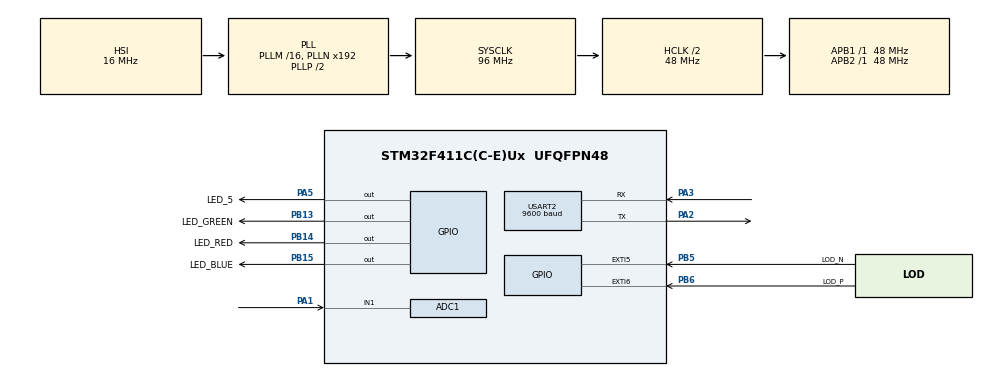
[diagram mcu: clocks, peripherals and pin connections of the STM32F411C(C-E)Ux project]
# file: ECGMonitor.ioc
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ADC1.Channel-3\#ChannelRegularConversion=ADC_CHANNEL_1
ADC1.ClockPrescaler=ADC_CLOCK_SYNC_PCLK_DIV6
ADC1.ContinuousConvMode=DISABLE
ADC1.DMAContinuousRequests=ENABLE
ADC1.ExternalTrigConv=ADC_EXTERNALTRIGCONV_T2_TRGO
ADC1.NbrOfConversion=1
ADC1.NbrOfConversionFlag=1
ADC1.Rank-3\#ChannelRegularConversion=1
ADC1.SamplingTime-3\#ChannelRegularConversion=ADC_SAMPLETIME_3CYCLES
ADC1.master=1
Dma.ADC1.0.Direction=DMA_PERIPH_TO_MEMORY
Dma.ADC1.0.FIFOMode=DMA_FIFOMODE_DISABLE
Dma.ADC1.0.Instance=DMA2_Stream0
Dma.ADC1.0.MemDataAlignment=DMA_MDATAALIGN_HALFWORD
Dma.ADC1.0.MemInc=DMA_MINC_ENABLE
Dma.ADC1.0.Mode=DMA_CIRCULAR
Dma.ADC1.0.PeriphDataAlignment=DMA_PDATAALIGN_HALFWORD
Dma.ADC1.0.PeriphInc=DMA_PINC_DISABLE
Dma.ADC1.0.Priority=DMA_PRIORITY_HIGH
Dma.Request0=ADC1
Mcu.Family=STM32F4
Mcu.Name=STM32F411C(C-E)Ux
Mcu.Package=UFQFPN48
NVIC.DMA2_Stream0_IRQn=true\:0\:0\:false\:false\:true\:false\:true\:true
NVIC.EXTI9_5_IRQn=true\:0\:0\:false\:false\:true\:true\:true\:true
NVIC.PriorityGroup=NVIC_PRIORITYGROUP_4
NVIC.TIM2_IRQn=true\:0\:0\:false\:false\:true\:true\:true\:true
PA1.Signal=ADCx_IN1
PA2.Mode=Asynchronous
PA2.Signal=USART2_TX
PA3.Mode=Asynchronous
PA3.Signal=USART2_RX
PA5.GPIO_Label=LED_5
PA5.GPIO_Speed=GPIO_SPEED_FREQ_MEDIUM
PA5.Signal=GPIO_Output
PB13.GPIO_Label=LED_GREEN
PB13.PinState=GPIO_PIN_SET
PB13.Signal=GPIO_Output
PB14.GPIO_Label=LED_RED
PB14.Signal=GPIO_Output
PB15.GPIO_Label=LED_BLUE
PB15.PinState=GPIO_PIN_SET
PB15.Signal=GPIO_Output
PB5.GPIO_Label=LOD_N
PB5.GPIO_ModeDefaultEXTI=GPIO_MODE_IT_RISING_FALLING
PB5.Signal=GPXTI5
PB6.GPIO_Label=LOD_P
PB6.GPIO_ModeDefaultEXTI=GPIO_MODE_IT_RISING_FALLING
PB6.Signal=GPXTI6
PH0\ -\ OSC_IN.Mode=HSE-External-Oscillator
PH0\ -\ OSC_IN.Signal=RCC_OSC_IN
PH1\ -\ OSC_OUT.Mode=HSE-External-Oscillator
PH1\ -\ OSC_OUT.Signal=RCC_OSC_OUT
ProjectManager.HeapSize=0x200
ProjectManager.StackSize=0x400
ProjectManager.TargetToolchain=Makefile
RCC.AHBCLKDivider=RCC_SYSCLK_DIV2
RCC.AHBFreq_Value=48000000
RCC.APB1Freq_Value=48000000
RCC.APB1TimFreq_Value=48000000
RCC.APB2Freq_Value=48000000
RCC.APB2TimFreq_Value=48000000
RCC.CortexFreq_Value=48000000
RCC.HCLKFreq_Value=48000000
RCC.HSE_VALUE=8000000
RCC.HSI_VALUE=16000000
RCC.LSE_VALUE=32768
RCC.SYSCLKFreq_VALUE=96000000
RCC.SYSCLKSource=RCC_SYSCLKSOURCE_PLLCLK
RCC.VCOOutputFreq_Value=192000000
SH.ADCx_IN1.0=ADC1_IN1,IN1
TIM2.AutoReloadPreload=TIM_AUTORELOAD_PRELOAD_ENABLE
TIM2.Channel-PWM\ Generation1\ No\ Output=TIM_CHANNEL_1
TIM2.ClockDivision=TIM_CLOCKDIVISION_DIV1
TIM2.Period=512
TIM2.TIM_MasterOutputTrigger=TIM_TRGO_UPDATE
USART2.BaudRate=9600
USART2.Parity=PARITY_NONE
USART2.VirtualMode=VM_ASYNC
USART2.WordLength=WORDLENGTH_8B
VP_TIM2_VS_ClockSourceINT.Mode=Internal
VP_TIM2_VS_no_output1.Mode=PWM Generation1 No Output
board=custom

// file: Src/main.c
/* USER CODE BEGIN Header */
/**
  ******************************************************************************
  * @file           : main.c
  * @brief          : Main program body
  ******************************************************************************
  * @attention
  *
  * Copyright (c) 2023 STMicroelectronics.
  * All rights reserved.
  *
  * This software is licensed under terms that can be found in the LICENSE file
  * in the root directory of this software component.
  * If no LICENSE file comes with this software, it is provided AS-IS.
  *
  ******************************************************************************
  */
/* USER CODE END Header */
#include "main.h"
#include "adc.h"
#include "dma.h"
#include "tim.h"
#include "usart.h"
#include "gpio.h"

/* USER CODE BEGIN Includes */
#include "serial/print.h"
#include "adc_buffer.h"
/* USER CODE END Includes */

void SystemClock_Config(void);

int main(void)
{

  /* MCU Configuration--------------------------------------------------------*/

  /* Reset of all peripherals, Initializes the Flash interface and the Systick. */
  HAL_Init();

  /* Configure the system clock */
  SystemClock_Config();

  /* Initialize all configured peripherals */
  MX_GPIO_Init();
  MX_DMA_Init();
  MX_ADC1_Init();
  MX_USART2_UART_Init();
  MX_TIM2_Init();
  /* USER CODE BEGIN 2 */

  HAL_TIM_Base_Start_IT(&htim2);

  HAL_ADC_Start_DMA(&hadc1, (uint32_t*)adc_buffer, ADC_BUF_LEN);

  cpp_main();
  /* USER CODE END 2 */

  /* Infinite loop */
  while (1)
  {

  }
}

void SystemClock_Config(void)
{
  RCC_OscInitTypeDef RCC_OscInitStruct = {0};
  RCC_ClkInitTypeDef RCC_ClkInitStruct = {0};

  /** Configure the main internal regulator output voltage
  */
  __HAL_RCC_PWR_CLK_ENABLE();
  __HAL_PWR_VOLTAGESCALING_CONFIG(PWR_REGULATOR_VOLTAGE_SCALE1);

  /** Initializes the RCC Oscillators according to the specified parameters
  * in the RCC_OscInitTypeDef structure.
  */
  RCC_OscInitStruct.OscillatorType = RCC_OSCILLATORTYPE_HSI;
  RCC_OscInitStruct.HSIState = RCC_HSI_ON;
  RCC_OscInitStruct.HSICalibrationValue = RCC_HSICALIBRATION_DEFAULT;
  RCC_OscInitStruct.PLL.PLLState = RCC_PLL_ON;
  RCC_OscInitStruct.PLL.PLLSource = RCC_PLLSOURCE_HSI;
  RCC_OscInitStruct.PLL.PLLM = 16;
  RCC_OscInitStruct.PLL.PLLN = 192;
  RCC_OscInitStruct.PLL.PLLP = RCC_PLLP_DIV2;
  RCC_OscInitStruct.PLL.PLLQ = 4;
  if (HAL_RCC_OscConfig(&RCC_OscInitStruct) != HAL_OK)
  {
    Error_Handler();
  }

  /** Initializes the CPU, AHB and APB buses clocks
  */
  RCC_ClkInitStruct.ClockType = RCC_CLOCKTYPE_HCLK|RCC_CLOCKTYPE_SYSCLK
                              |RCC_CLOCKTYPE_PCLK1|RCC_CLOCKTYPE_PCLK2;
  RCC_ClkInitStruct.SYSCLKSource = RCC_SYSCLKSOURCE_PLLCLK;
  RCC_ClkInitStruct.AHBCLKDivider = RCC_SYSCLK_DIV2;
  RCC_ClkInitStruct.APB1CLKDivider = RCC_HCLK_DIV1;
  RCC_ClkInitStruct.APB2CLKDivider = RCC_HCLK_DIV1;

  if (HAL_RCC_ClockConfig(&RCC_ClkInitStruct, FLASH_LATENCY_1) != HAL_OK)
  {
    Error_Handler();
  }
}

void Error_Handler(void)
{
  __disable_irq();
  while (1)
  {
  }
}
